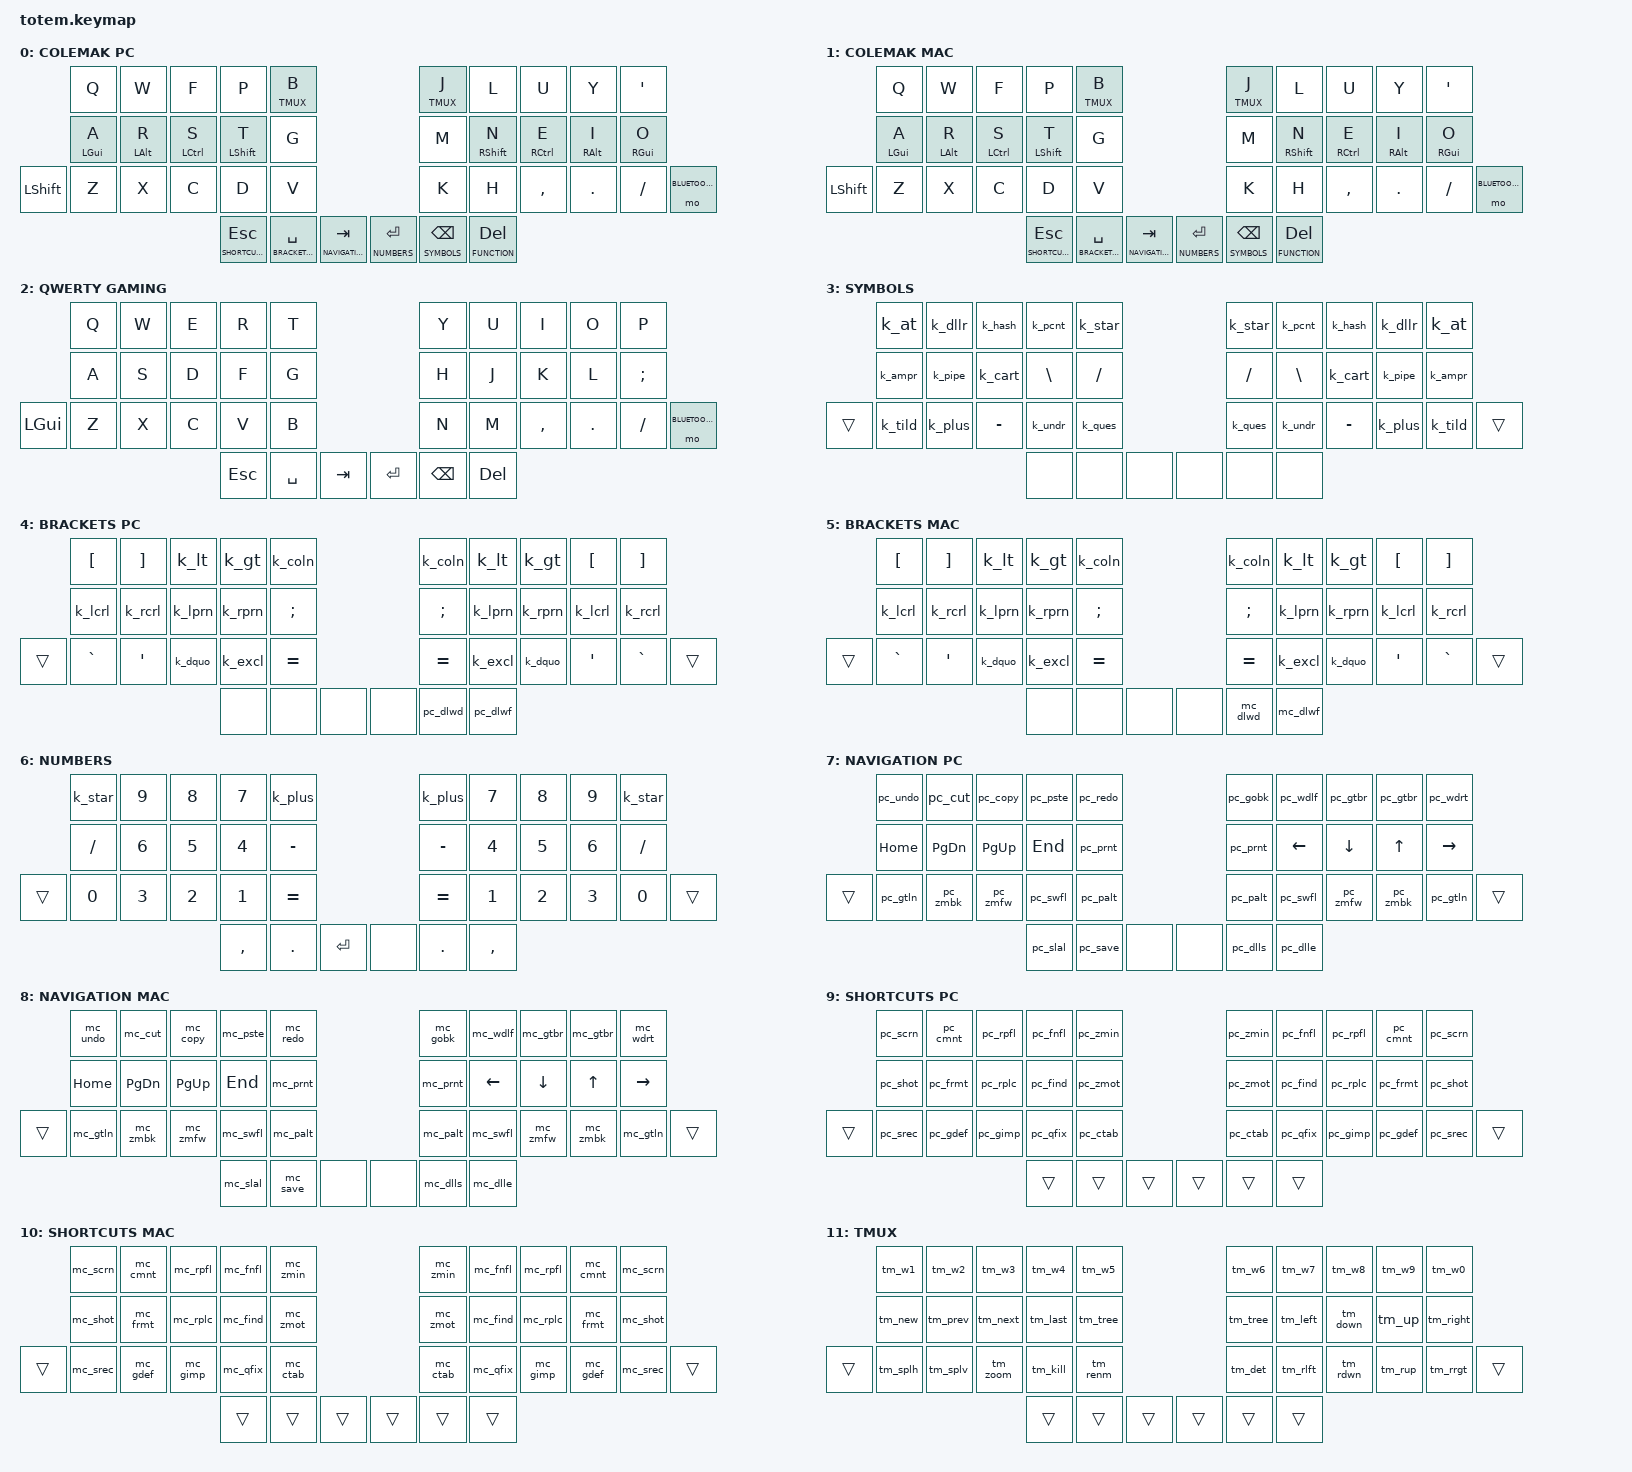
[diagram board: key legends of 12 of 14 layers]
#include <behaviors.dtsi>
#include <dt-bindings/zmk/keys.h>
#include <dt-bindings/zmk/bt.h>
#include <dt-bindings/zmk/outputs.h>

#define COLEMAK_PC 0
#define COLEMAK_MAC 1
#define QWERTY_GAMING 2
#define SYMBOLS 3
#define BRACKETS_PC 4
#define BRACKETS_MAC 5
#define NUMBERS 6
#define NAVIGATION_PC 7
#define NAVIGATION_MAC 8
#define SHORTCUTS_PC 9
#define SHORTCUTS_MAC 10
#define TMUX 11
#define FUNCTION 12
#define BLUETOOTH 13

// Home row mods
#define hm_a &mt LGUI A
#define hm_r &mt LALT R
#define hm_s &mt LCTRL S
#define hm_t &mt LSHFT T
#define hm_n &mt RSHFT N
#define hm_e &mt RCTRL E
#define hm_i &mt RALT I
#define hm_o &mt RGUI O

// Layer switches
#define to_pc &to COLEMAK_PC
#define to_mac &to COLEMAK_MAC
#define to_game &to QWERTY_GAMING
#define mo_bt &mo BLUETOOTH
#define tmux_l &lt TMUX B
#define tmux_r &lt TMUX J

// PC Layer-tap (must be #define, not ZMK macros)
#define pcl_sh &lt SHORTCUTS_PC ESC
#define pcl_br &lt BRACKETS_PC SPACE
#define pcl_na &lt NAVIGATION_PC TAB
#define pcl_nu &lt NUMBERS RET
#define pcl_sy &lt SYMBOLS BSPC
#define pcl_fn &lt FUNCTION DEL

// Mac Layer-tap
#define mcl_sh &lt SHORTCUTS_MAC ESC
#define mcl_br &lt BRACKETS_MAC SPACE
#define mcl_na &lt NAVIGATION_MAC TAB
#define mcl_nu &lt NUMBERS RET
#define mcl_sy &lt SYMBOLS BSPC
#define mcl_fn &lt FUNCTION DEL

// PC Shortcuts
#define pc_scrn kp PSCRN
#define pc_cmnt kp LC(FSLH)
#define pc_rpfl kp LC(LS(H))
#define pc_fnfl kp LC(LS(F))
#define pc_zmin kp LC(LS(EQUAL))
#define pc_zmot kp LC(MINUS)
#define pc_shot kp LG(LS(S))
#define pc_frmt kp LS(LA(F))
#define pc_rplc kp LC(H)
#define pc_find kp LC(F)
#define pc_srec kp LG(LA(R))
#define pc_gdef kp F12
#define pc_gimp kp LC(F12)
#define pc_qfix kp LC(DOT)
#define pc_ctab kp LC(W)
#define pc_capp kp LA(F4)

// Mac Shortcuts
#define mc_scrn kp LG(LS(N3))
#define mc_cmnt kp LG(FSLH)
#define mc_rpfl kp LG(LS(H))
#define mc_fnfl kp LG(LS(F))
#define mc_zmin kp LG(LS(EQUAL))
#define mc_zmot kp LG(MINUS)
#define mc_shot kp LG(LS(N4))
#define mc_frmt kp LS(LA(F))
#define mc_rplc kp LG(LA(F))
#define mc_find kp LG(F)
#define mc_srec kp LG(LS(N5))
#define mc_gdef kp F12
#define mc_gimp kp LG(F12)
#define mc_qfix kp LG(DOT)
#define mc_ctab kp LG(W)
#define mc_capp kp LG(Q)

// Shifted number symbols: ! @ # $ % ^ & * ( )
#define k_excl kp LS(N1)
#define k_at kp LS(N2)
#define k_hash kp LS(N3)
#define k_dllr kp LS(N4)
#define k_pcnt kp LS(N5)
#define k_cart kp LS(N6)
#define k_ampr kp LS(N7)
#define k_star kp LS(N8)
#define k_lprn kp LS(N9)
#define k_rprn kp LS(N0)

// Shifted punctuation
#define k_pipe kp LS(BSLH)
#define k_plus kp LS(EQUAL)
#define k_undr kp LS(MINUS)
#define k_tild kp LS(GRAVE)
#define k_lcrl kp LS(LBKT)
#define k_rcrl kp LS(RBKT)
#define k_lt kp LS(COMMA)
#define k_gt kp LS(DOT)
#define k_coln kp LS(SEMI)
#define k_dquo kp LS(SQT)
#define k_ques kp LS(FSLH)

// PC Navigation
#define pc_undo kp LC(Z)
#define pc_redo kp LC(LS(Z))
#define pc_cut kp LC(X)
#define pc_copy kp LC(C)
#define pc_pste kp LC(V)
#define pc_slal kp LC(A)
#define pc_save kp LC(S)
#define pc_gtln kp LC(G)
#define pc_zmbk kp LC(MINUS)
#define pc_zmfw kp LC(EQUAL)
#define pc_swfl kp LC(LS(O))
#define pc_prnt kp LC(P)
#define pc_palt kp LC(LS(P))

// Mac Navigation
#define mc_undo kp LG(Z)
#define mc_redo kp LG(LS(Z))
#define mc_cut kp LG(X)
#define mc_copy kp LG(C)
#define mc_pste kp LG(V)
#define mc_slal kp LG(A)
#define mc_save kp LG(S)
#define mc_gtln kp LC(G)
#define mc_zmbk kp LG(MINUS)
#define mc_zmfw kp LG(EQUAL)
#define mc_swfl kp LG(LS(O))
#define mc_prnt kp LG(P)
#define mc_palt kp LG(LS(P))

// Delete word / line
#define pc_dlwd kp LC(BSPC)
#define pc_dlwf kp LC(DEL)
#define mc_dlwd kp LA(BSPC)
#define mc_dlwf kp LA(DEL)
#define mc_dlls kp LG(BSPC)
#define mc_dlle kp LC(K)

// Word movement
#define pc_wdlf kp LC(LEFT)
#define pc_wdrt kp LC(RIGHT)
#define mc_wdlf kp LA(LEFT)
#define mc_wdrt kp LA(RIGHT)

// Go to matching bracket
#define pc_gtbr kp LC(LS(BSLH))
#define mc_gtbr kp LG(LS(BSLH))

// Go back (previous cursor position)
#define pc_gobk kp LA(LEFT)
#define mc_gobk kp LC(MINUS)

&mt {
  quick-tap-ms = <100>;
  global-quick-tap;
  flavor = "tap-preferred";
  tapping-term-ms = <170>;
};

/ {
        macros {
                // BT profile macros
                bt0_pc: bt0_pc {
                        compatible = "zmk,behavior-macro";
                        #binding-cells = <0>;
                        bindings = <&bt BT_SEL 0>, <&to COLEMAK_PC>;
                };
                bt1_mac: bt1_mac {
                        compatible = "zmk,behavior-macro";
                        #binding-cells = <0>;
                        bindings = <&bt BT_SEL 1>, <&to COLEMAK_MAC>;
                };
                bt2: bt2 { compatible = "zmk,behavior-macro"; #binding-cells = <0>; bindings = <&bt BT_SEL 2>; };
                bt3: bt3 { compatible = "zmk,behavior-macro"; #binding-cells = <0>; bindings = <&bt BT_SEL 3>; };
                bt4: bt4 { compatible = "zmk,behavior-macro"; #binding-cells = <0>; bindings = <&bt BT_SEL 4>; };

                // Multi-step delete to line start/end macros
                pc_dlls: pc_dlls { compatible = "zmk,behavior-macro"; #binding-cells = <0>; bindings = <&kp LS(HOME)>, <&kp BSPC>; };
                pc_dlle: pc_dlle { compatible = "zmk,behavior-macro"; #binding-cells = <0>; bindings = <&kp LS(END)>, <&kp DEL>; };

                // tmux prefix macros. Keep these aligned with ~/.tmux/keybindings.conf.
                tm_w1: tm_w1 { compatible = "zmk,behavior-macro"; #binding-cells = <0>; bindings = <&kp LC(A)>, <&kp N1>; };
                tm_w2: tm_w2 { compatible = "zmk,behavior-macro"; #binding-cells = <0>; bindings = <&kp LC(A)>, <&kp N2>; };
                tm_w3: tm_w3 { compatible = "zmk,behavior-macro"; #binding-cells = <0>; bindings = <&kp LC(A)>, <&kp N3>; };
                tm_w4: tm_w4 { compatible = "zmk,behavior-macro"; #binding-cells = <0>; bindings = <&kp LC(A)>, <&kp N4>; };
                tm_w5: tm_w5 { compatible = "zmk,behavior-macro"; #binding-cells = <0>; bindings = <&kp LC(A)>, <&kp N5>; };
                tm_w6: tm_w6 { compatible = "zmk,behavior-macro"; #binding-cells = <0>; bindings = <&kp LC(A)>, <&kp N6>; };
                tm_w7: tm_w7 { compatible = "zmk,behavior-macro"; #binding-cells = <0>; bindings = <&kp LC(A)>, <&kp N7>; };
                tm_w8: tm_w8 { compatible = "zmk,behavior-macro"; #binding-cells = <0>; bindings = <&kp LC(A)>, <&kp N8>; };
                tm_w9: tm_w9 { compatible = "zmk,behavior-macro"; #binding-cells = <0>; bindings = <&kp LC(A)>, <&kp N9>; };
                tm_w0: tm_w0 { compatible = "zmk,behavior-macro"; #binding-cells = <0>; bindings = <&kp LC(A)>, <&kp N0>; };
                tm_new: tm_new { compatible = "zmk,behavior-macro"; #binding-cells = <0>; bindings = <&kp LC(A)>, <&kp C>; };
                tm_prev: tm_prev { compatible = "zmk,behavior-macro"; #binding-cells = <0>; bindings = <&kp LC(A)>, <&kp P>; };
                tm_next: tm_next { compatible = "zmk,behavior-macro"; #binding-cells = <0>; bindings = <&kp LC(A)>, <&kp N>; };
                tm_last: tm_last { compatible = "zmk,behavior-macro"; #binding-cells = <0>; bindings = <&kp LC(A)>, <&kp L>; };
                tm_tree: tm_tree { compatible = "zmk,behavior-macro"; #binding-cells = <0>; bindings = <&kp LC(A)>, <&kp W>; };
                tm_left: tm_left { compatible = "zmk,behavior-macro"; #binding-cells = <0>; bindings = <&kp LC(A)>, <&kp LEFT>; };
                tm_down: tm_down { compatible = "zmk,behavior-macro"; #binding-cells = <0>; bindings = <&kp LC(A)>, <&kp DOWN>; };
                tm_up: tm_up { compatible = "zmk,behavior-macro"; #binding-cells = <0>; bindings = <&kp LC(A)>, <&kp UP>; };
                tm_right: tm_right { compatible = "zmk,behavior-macro"; #binding-cells = <0>; bindings = <&kp LC(A)>, <&kp RIGHT>; };
                tm_splh: tm_splh { compatible = "zmk,behavior-macro"; #binding-cells = <0>; bindings = <&kp LC(A)>, <&kp H>; };
                tm_splv: tm_splv { compatible = "zmk,behavior-macro"; #binding-cells = <0>; bindings = <&kp LC(A)>, <&kp V>; };
                tm_zoom: tm_zoom { compatible = "zmk,behavior-macro"; #binding-cells = <0>; bindings = <&kp LC(A)>, <&kp Z>; };
                tm_kill: tm_kill { compatible = "zmk,behavior-macro"; #binding-cells = <0>; bindings = <&kp LC(A)>, <&kp X>; };
                tm_renm: tm_renm { compatible = "zmk,behavior-macro"; #binding-cells = <0>; bindings = <&kp LC(A)>, <&kp COMMA>; };
                tm_det: tm_det { compatible = "zmk,behavior-macro"; #binding-cells = <0>; bindings = <&kp LC(A)>, <&kp D>; };
                tm_rlft: tm_rlft { compatible = "zmk,behavior-macro"; #binding-cells = <0>; bindings = <&kp LC(A)>, <&kp LS(H)>; };
                tm_rdwn: tm_rdwn { compatible = "zmk,behavior-macro"; #binding-cells = <0>; bindings = <&kp LC(A)>, <&kp LS(J)>; };
                tm_rup: tm_rup { compatible = "zmk,behavior-macro"; #binding-cells = <0>; bindings = <&kp LC(A)>, <&kp LS(K)>; };
                tm_rrgt: tm_rrgt { compatible = "zmk,behavior-macro"; #binding-cells = <0>; bindings = <&kp LC(A)>, <&kp LS(L)>; };
        };

        keymap {
                compatible = "zmk,keymap";

                colemak_pc_layer {
label= "COLEMAK PC";
bindings = <
           &kp Q  &kp W  &kp F  &kp P   tmux_l                      tmux_r  &kp L   &kp U      &kp Y    &kp SQT
           hm_a   hm_r   hm_s   hm_t    &kp G                       &kp M   hm_n    hm_e       hm_i     hm_o
&kp LSHFT  &kp Z  &kp X  &kp C  &kp D   &kp V                       &kp K   &kp H   &kp COMMA  &kp DOT  &kp FSLH  mo_bt
                                pcl_sh  pcl_br  pcl_na      pcl_nu  pcl_sy  pcl_fn
>;
                };

                colemak_mac_layer {
label= "COLEMAK MAC";
bindings = <
           &kp Q  &kp W  &kp F  &kp P   tmux_l                      tmux_r  &kp L   &kp U      &kp Y    &kp SQT
           hm_a   hm_r   hm_s   hm_t    &kp G                       &kp M   hm_n    hm_e       hm_i     hm_o
&kp LSHFT  &kp Z  &kp X  &kp C  &kp D   &kp V                       &kp K   &kp H   &kp COMMA  &kp DOT  &kp FSLH  mo_bt
                                mcl_sh  mcl_br  mcl_na      mcl_nu  mcl_sy  mcl_fn
>;
                };

                qwerty_gaming_layer {
label= "QWERTY GAMING";
bindings = <
          &kp Q  &kp W  &kp E  &kp R    &kp T                            &kp Y     &kp U    &kp I      &kp O    &kp P
          &kp A  &kp S  &kp D  &kp F    &kp G                            &kp H     &kp J    &kp K      &kp L    &kp SEMI
&kp LGUI  &kp Z  &kp X  &kp C  &kp V    &kp B                            &kp N     &kp M    &kp COMMA  &kp DOT  &kp FSLH  mo_bt
                               &kp ESC  &kp SPACE  &kp TAB      &kp RET  &kp BSPC  &kp DEL
>;
                };

                symbols_layer {
label= "SYMBOLS";
bindings = <
        &k_at    &k_dllr  &k_hash    &k_pcnt   &k_star                     &k_star   &k_pcnt   &k_hash    &k_dllr  &k_at
        &k_ampr  &k_pipe  &k_cart    &kp BSLH  &kp FSLH                    &kp FSLH  &kp BSLH  &k_cart    &k_pipe  &k_ampr
&trans  &k_tild  &k_plus  &kp MINUS  &k_undr   &k_ques                     &k_ques   &k_undr   &kp MINUS  &k_plus  &k_tild  &trans
                                     &none     &none     &none      &none  &none     &none
>;
                };

                brackets_pc_layer {
label= "BRACKETS PC";
bindings = <
        &kp LBKT   &kp RBKT  &k_lt    &k_gt    &k_coln                      &k_coln    &k_lt     &k_gt    &kp LBKT  &kp RBKT
        &k_lcrl    &k_rcrl   &k_lprn  &k_rprn  &kp SEMI                     &kp SEMI   &k_lprn   &k_rprn  &k_lcrl   &k_rcrl
&trans  &kp GRAVE  &kp SQT   &k_dquo  &k_excl  &kp EQUAL                    &kp EQUAL  &k_excl   &k_dquo  &kp SQT   &kp GRAVE  &trans
                                      &none    &none      &none      &none  &pc_dlwd   &pc_dlwf
>;
                };

                brackets_mac_layer {
label= "BRACKETS MAC";
bindings = <
        &kp LBKT   &kp RBKT  &k_lt    &k_gt    &k_coln                      &k_coln    &k_lt     &k_gt    &kp LBKT  &kp RBKT
        &k_lcrl    &k_rcrl   &k_lprn  &k_rprn  &kp SEMI                     &kp SEMI   &k_lprn   &k_rprn  &k_lcrl   &k_rcrl
&trans  &kp GRAVE  &kp SQT   &k_dquo  &k_excl  &kp EQUAL                    &kp EQUAL  &k_excl   &k_dquo  &kp SQT   &kp GRAVE  &trans
                                      &none    &none      &none      &none  &mc_dlwd   &mc_dlwf
>;
                };

                numbers_layer {
label= "NUMBERS";
bindings = <
        &k_star   &kp N9  &kp N8  &kp N7     &k_plus                        &k_plus    &kp N7     &kp N8  &kp N9  &k_star
        &kp FSLH  &kp N6  &kp N5  &kp N4     &kp MINUS                      &kp MINUS  &kp N4     &kp N5  &kp N6  &kp FSLH
&trans  &kp N0    &kp N3  &kp N2  &kp N1     &kp EQUAL                      &kp EQUAL  &kp N1     &kp N2  &kp N3  &kp N0    &trans
                                  &kp COMMA  &kp DOT    &kp RET      &none  &kp DOT    &kp COMMA
>;
                };

                navigation_pc_layer {
label= "NAVIGATION PC";
bindings = <
        &pc_undo  &pc_cut    &pc_copy   &pc_pste  &pc_redo                    &pc_gobk  &pc_wdlf  &pc_gtbr  &pc_gtbr  &pc_wdrt
        &kp HOME  &kp PG_DN  &kp PG_UP  &kp END   &pc_prnt                    &pc_prnt  &kp LEFT  &kp DOWN  &kp UP    &kp RIGHT
&trans  &pc_gtln  &pc_zmbk   &pc_zmfw   &pc_swfl  &pc_palt                    &pc_palt  &pc_swfl  &pc_zmfw  &pc_zmbk  &pc_gtln   &trans
                                        &pc_slal  &pc_save  &none      &none  &pc_dlls  &pc_dlle
>;
                };

                navigation_mac_layer {
label= "NAVIGATION MAC";
bindings = <
        &mc_undo  &mc_cut    &mc_copy   &mc_pste  &mc_redo                    &mc_gobk  &mc_wdlf  &mc_gtbr  &mc_gtbr  &mc_wdrt
        &kp HOME  &kp PG_DN  &kp PG_UP  &kp END   &mc_prnt                    &mc_prnt  &kp LEFT  &kp DOWN  &kp UP    &kp RIGHT
&trans  &mc_gtln  &mc_zmbk   &mc_zmfw   &mc_swfl  &mc_palt                    &mc_palt  &mc_swfl  &mc_zmfw  &mc_zmbk  &mc_gtln   &trans
                                        &mc_slal  &mc_save  &none      &none  &mc_dlls  &mc_dlle
>;
                };

                shortcuts_pc_layer {
label= "SHORTCUTS PC";
bindings = <
        &pc_scrn  &pc_cmnt  &pc_rpfl  &pc_fnfl  &pc_zmin                      &pc_zmin  &pc_fnfl  &pc_rpfl  &pc_cmnt  &pc_scrn
        &pc_shot  &pc_frmt  &pc_rplc  &pc_find  &pc_zmot                      &pc_zmot  &pc_find  &pc_rplc  &pc_frmt  &pc_shot
&trans  &pc_srec  &pc_gdef  &pc_gimp  &pc_qfix  &pc_ctab                      &pc_ctab  &pc_qfix  &pc_gimp  &pc_gdef  &pc_srec  &trans
                                      &trans    &trans    &trans      &trans  &trans    &trans
>;
                };

                shortcuts_mac_layer {
label= "SHORTCUTS MAC";
bindings = <
        &mc_scrn  &mc_cmnt  &mc_rpfl  &mc_fnfl  &mc_zmin                      &mc_zmin  &mc_fnfl  &mc_rpfl  &mc_cmnt  &mc_scrn
        &mc_shot  &mc_frmt  &mc_rplc  &mc_find  &mc_zmot                      &mc_zmot  &mc_find  &mc_rplc  &mc_frmt  &mc_shot
&trans  &mc_srec  &mc_gdef  &mc_gimp  &mc_qfix  &mc_ctab                      &mc_ctab  &mc_qfix  &mc_gimp  &mc_gdef  &mc_srec  &trans
                                      &trans    &trans    &trans      &trans  &trans    &trans
>;
                };

                tmux_layer {
label= "TMUX";
bindings = <
        &tm_w1    &tm_w2    &tm_w3    &tm_w4    &tm_w5                        &tm_w6    &tm_w7    &tm_w8    &tm_w9   &tm_w0
        &tm_new   &tm_prev  &tm_next  &tm_last  &tm_tree                      &tm_tree  &tm_left  &tm_down  &tm_up   &tm_right
&trans  &tm_splh  &tm_splv  &tm_zoom  &tm_kill  &tm_renm                      &tm_det   &tm_rlft  &tm_rdwn  &tm_rup  &tm_rrgt   &trans
                                      &trans    &trans    &trans      &trans  &trans    &trans
>;
                };

                function_layer {
label= "FUNCTION";
bindings = <
        to_pc    &kp F9  &kp F8  &kp F7  &kp F10                    &kp F10  &kp F7  &kp F8  &kp F9  to_pc
        to_mac   &kp F6  &kp F5  &kp F4  &kp F11                    &kp F11  &kp F4  &kp F5  &kp F6  to_mac
&trans  to_game  &kp F3  &kp F2  &kp F1  &kp F12                    &kp F12  &kp F1  &kp F2  &kp F3  to_game  &trans
                                 &none   &none    &none      &none  &none    &none
>;
                };

                bluetooth_layer {
label= "BLUETOOTH";
bindings = <
        &bt0_pc     &bt1_mac      &bt2        &bt3         &bt4                        &trans  &trans  &trans  &trans  to_pc
        &trans      &trans        &trans      &trans       &trans                      &trans  &trans  &trans  &trans  to_mac
&trans  &bt BT_CLR  &out OUT_TOG  &sys_reset  &bootloader  &trans                      &trans  &trans  &trans  &trans  to_game  &trans
                                              &trans       &trans  &trans      &trans  &trans  &trans
>;
                };
        };
};
